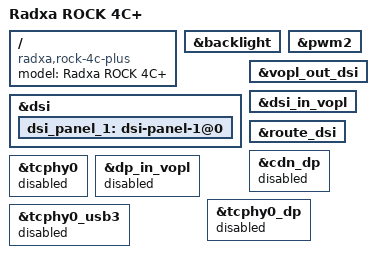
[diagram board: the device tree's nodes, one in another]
/dts-v1/;
/plugin/;

/ {
	model = "Radxa ROCK 4C+";
	compatible = "radxa,rock-4c-plus", "rockchip,rk3399";

	fragment@0 {
		target = <&backlight>;

		__overlay__ {
			status = "okay";
		};
	};

	fragment@1 {
		target = <&pwm2>;

		__overlay__ {
			status = "okay";
		};
	};

	fragment@2 {
		target = <&dsi>;

		__overlay__ {
			status = "okay";
			dsi_panel_1: dsi-panel-1@0 {
				status = "okay";
			};
		};
	};

	fragment@3 {
		target = <&vopl_out_dsi>;

		__overlay__ {
			status = "okay";
		};
	};

	fragment@4 {
		target = <&dsi_in_vopl>;

		__overlay__ {
			status = "okay";
		};
	};

	fragment@5 {
		target = <&route_dsi>;

		__overlay__ {
			status = "okay";
		};
	};

	fragment@6 {
		target = <&cdn_dp>;

		__overlay__ {
			status = "disabled";
		};
	};

	fragment@7 {
		target = <&tcphy0>;

		__overlay__ {
			status = "disabled";
		};
	};

	fragment@8 {
		target = <&dp_in_vopl>;

		__overlay__ {
			status = "disabled";
		};
	};

	fragment@9 {
		target = <&tcphy0_dp>;

		__overlay__ {
			status = "disabled";
		};
	};

	fragment@10 {
		target = <&tcphy0_usb3>;

		__overlay__ {
			status = "disabled";
		};
	};
};
